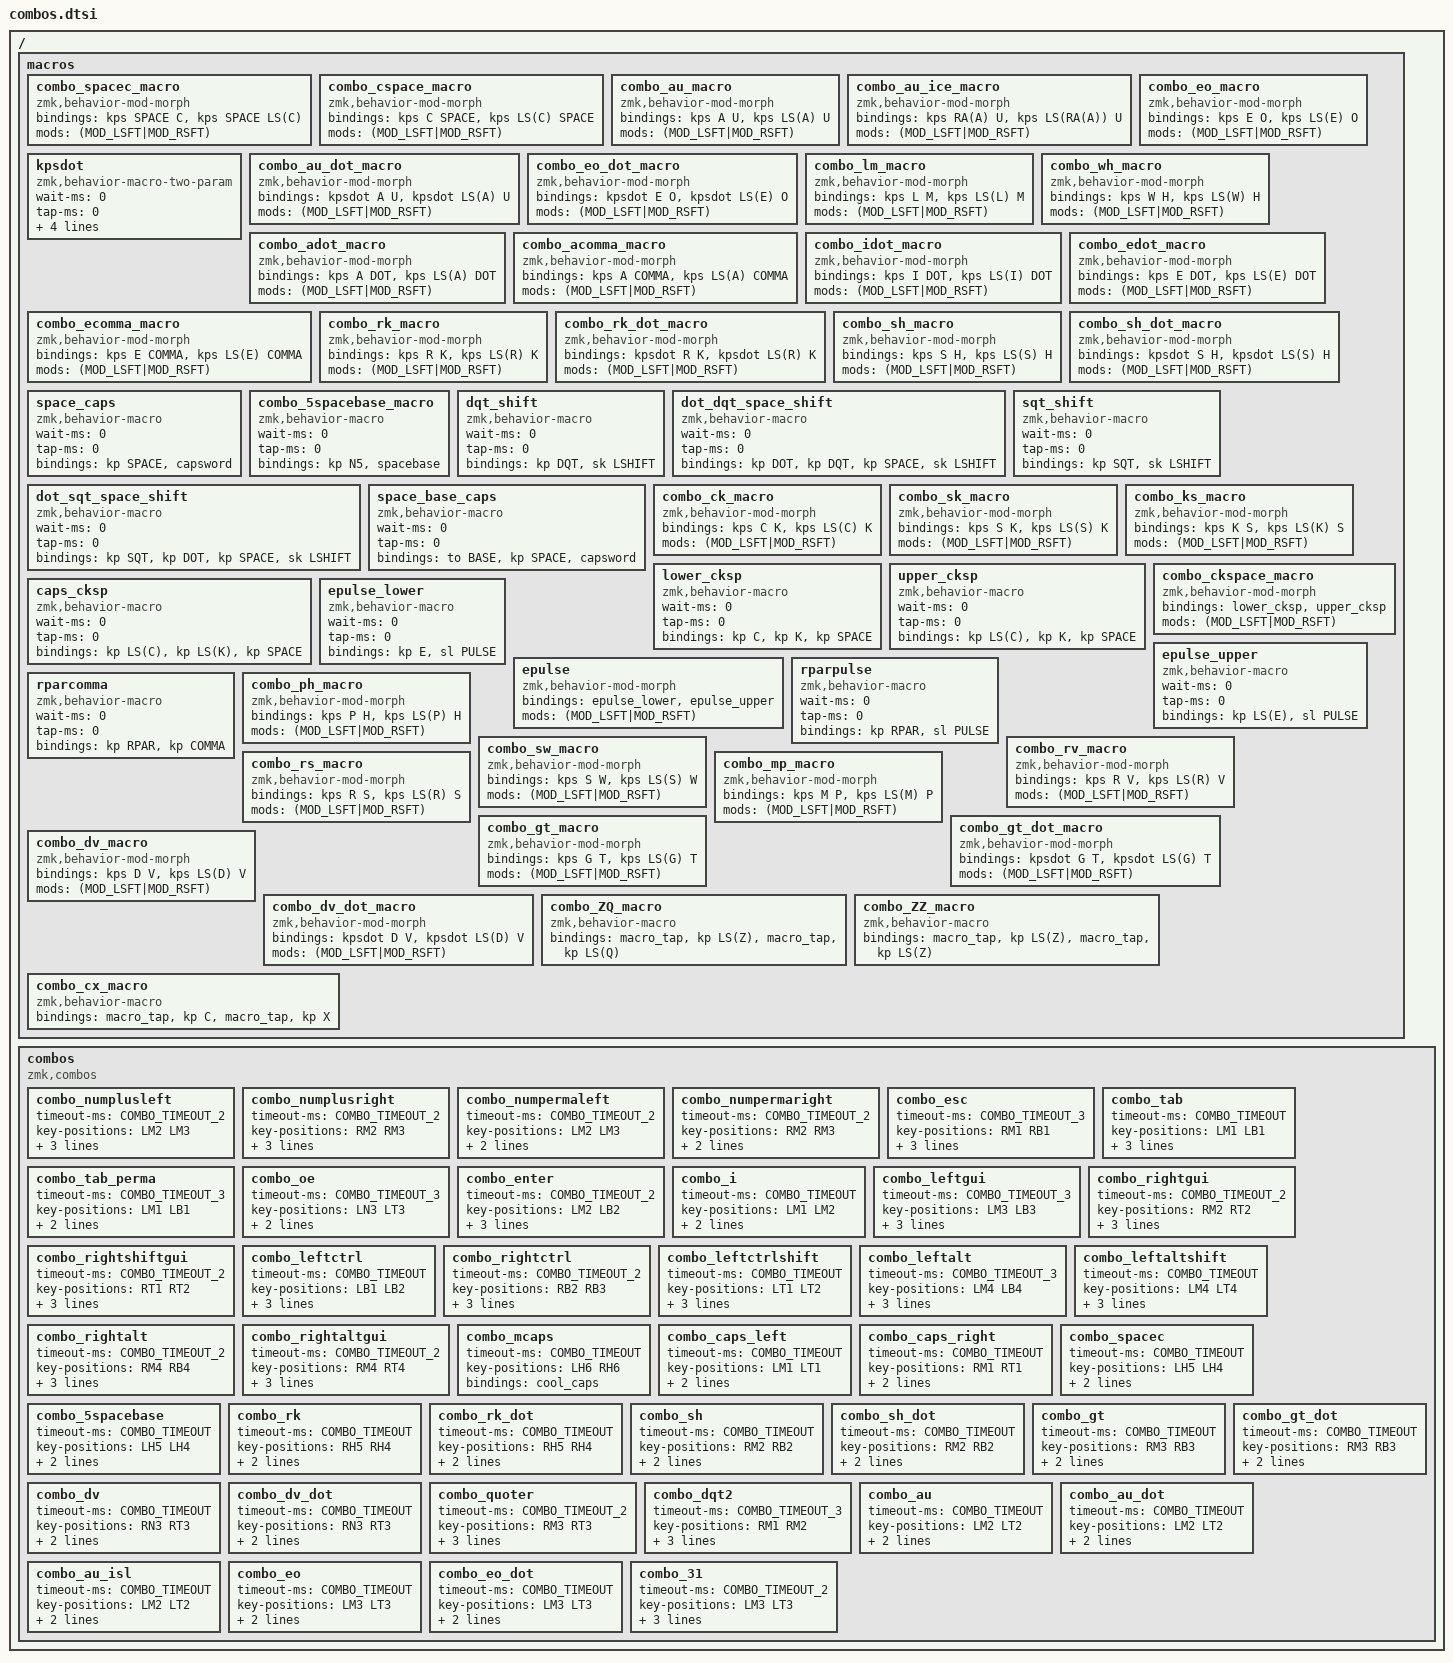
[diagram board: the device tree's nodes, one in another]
/ {
	macros {
		combo_spacec_macro: combo_spacec_macro {
			compatible = "zmk,behavior-mod-morph";
			#binding-cells = <0>;
			bindings = <&kps SPACE C>, <&kps SPACE LS(C)>;
			mods = <(MOD_LSFT|MOD_RSFT)>;
		};

		combo_cspace_macro: combo_cspace_macro {
			compatible = "zmk,behavior-mod-morph";
			#binding-cells = <0>;
			bindings = <&kps C SPACE>, <&kps LS(C) SPACE>;
			mods = <(MOD_LSFT|MOD_RSFT)>;
		};

		combo_au_macro: combo_au_macro {
			compatible = "zmk,behavior-mod-morph";
			#binding-cells = <0>;
			bindings = <&kps A U>, <&kps LS(A) U>;
			mods = <(MOD_LSFT|MOD_RSFT)>;
		};

		combo_au_ice_macro: combo_au_ice_macro {
			compatible = "zmk,behavior-mod-morph";
			#binding-cells = <0>;
			bindings = <&kps RA(A) U>, <&kps LS(RA(A)) U>;
			mods = <(MOD_LSFT|MOD_RSFT)>;
		};

		combo_eo_macro: combo_eo_macro {
			compatible = "zmk,behavior-mod-morph";
			#binding-cells = <0>;
			bindings = <&kps E O>, <&kps LS(E) O>;
			mods = <(MOD_LSFT|MOD_RSFT)>;
		};

		kpsdot: kpsdot {
			compatible = "zmk,behavior-macro-two-param";
			#binding-cells = <2>;
			wait-ms = <0>;
			tap-ms = <0>;
			bindings
				= <&macro_param_1to1>, <&kp MACRO_PLACEHOLDER>, <&kp DOT>
				, <&macro_param_2to1>, <&kp MACRO_PLACEHOLDER>, <&kp DOT>
				;
		};

		combo_au_dot_macro: combo_au_dot_macro {
			compatible = "zmk,behavior-mod-morph";
			#binding-cells = <0>;
			bindings = <&kpsdot A U>, <&kpsdot LS(A) U>;
			mods = <(MOD_LSFT|MOD_RSFT)>;
		};

		combo_eo_dot_macro: combo_eo_dot_macro {
			compatible = "zmk,behavior-mod-morph";
			#binding-cells = <0>;
			bindings = <&kpsdot E O>, <&kpsdot LS(E) O>;
			mods = <(MOD_LSFT|MOD_RSFT)>;
		};

		combo_lm_macro: combo_lm_macro {
			compatible = "zmk,behavior-mod-morph";
			#binding-cells = <0>;
			bindings = <&kps L M>, <&kps LS(L) M>;
			mods = <(MOD_LSFT|MOD_RSFT)>;
		};
		
		combo_wh_macro: combo_wh_macro {
			compatible = "zmk,behavior-mod-morph";
			#binding-cells = <0>;
			bindings = <&kps W H>, <&kps LS(W) H>;
			mods = <(MOD_LSFT|MOD_RSFT)>;
		};

		combo_adot_macro: combo_adot_macro {
			compatible = "zmk,behavior-mod-morph";
			#binding-cells = <0>;
			bindings = <&kps A DOT>, <&kps LS(A) DOT>;
			mods = <(MOD_LSFT|MOD_RSFT)>;
		};

		combo_acomma_macro: combo_acomma_macro {
			compatible = "zmk,behavior-mod-morph";
			#binding-cells = <0>;
			bindings = <&kps A COMMA>, <&kps LS(A) COMMA>;
			mods = <(MOD_LSFT|MOD_RSFT)>;
		};

		combo_idot_macro: combo_idot_macro {
			compatible = "zmk,behavior-mod-morph";
			#binding-cells = <0>;
			bindings = <&kps I DOT>, <&kps LS(I) DOT>;
			mods = <(MOD_LSFT|MOD_RSFT)>;
		};

		combo_edot_macro: combo_edot_macro {
			compatible = "zmk,behavior-mod-morph";
			#binding-cells = <0>;
			bindings = <&kps E DOT>, <&kps LS(E) DOT>;
			mods = <(MOD_LSFT|MOD_RSFT)>;
		};

		combo_ecomma_macro: combo_ecomma_macro {
			compatible = "zmk,behavior-mod-morph";
			#binding-cells = <0>;
			bindings = <&kps E COMMA>, <&kps LS(E) COMMA>;
			mods = <(MOD_LSFT|MOD_RSFT)>;
		};

		combo_rk_macro: combo_rk_macro {
			compatible = "zmk,behavior-mod-morph";
			#binding-cells = <0>;
			bindings = <&kps R K>, <&kps LS(R) K>;
			mods = <(MOD_LSFT|MOD_RSFT)>;
		};

		combo_rk_dot_macro: combo_rk_dot_macro {
			compatible = "zmk,behavior-mod-morph";
			#binding-cells = <0>;
			bindings = <&kpsdot R K>, <&kpsdot LS(R) K>;
			mods = <(MOD_LSFT|MOD_RSFT)>;
		};

		combo_sh_macro: combo_sh_macro {
			compatible = "zmk,behavior-mod-morph";
			#binding-cells = <0>;
			bindings = <&kps S H>, <&kps LS(S) H>;
			mods = <(MOD_LSFT|MOD_RSFT)>;
		};

		combo_sh_dot_macro: combo_sh_dot_macro {
			compatible = "zmk,behavior-mod-morph";
			#binding-cells = <0>;
			bindings = <&kpsdot S H>, <&kpsdot LS(S) H>;
			mods = <(MOD_LSFT|MOD_RSFT)>;
		};

		space_caps: space_caps {
			compatible = "zmk,behavior-macro";
			#binding-cells = <0>;
			wait-ms = <0>;
			tap-ms = <0>;
			bindings = <&kp SPACE &capsword>;
		};

		/* k_sqt: k_sqt { */
		/* 	compatible = "zmk,behavior-macro"; */
		/* 	#binding-cells = <0>; */
		/* 	wait-ms = <0>; */
		/* 	tap-ms = <0>; */
		/* 	bindings = <&kp K &sqt_nex>; */
		/* }; */

		combo_5spacebase_macro: combo_5spacebase_macro {
			compatible = "zmk,behavior-macro";
			#binding-cells = <0>;
			wait-ms = <0>;
			tap-ms = <0>;
			bindings = <&kp N5 &spacebase>;
		};

		dqt_shift: dqt_shift {
			compatible = "zmk,behavior-macro";
			#binding-cells = <0>;
			wait-ms = <0>;
			tap-ms = <0>;
			bindings = <&kp DQT &sk LSHIFT>;
		};

		dot_dqt_space_shift: dot_dqt_space_shift {
			compatible = "zmk,behavior-macro";
			#binding-cells = <0>;
			wait-ms = <0>;
			tap-ms = <0>;
			bindings = <&kp DOT &kp DQT &kp SPACE &sk LSHIFT>;
		};

		sqt_shift: sqt_shift {
			compatible = "zmk,behavior-macro";
			#binding-cells = <0>;
			wait-ms = <0>;
			tap-ms = <0>;
			bindings = <&kp SQT &sk LSHIFT>;
		};

		dot_sqt_space_shift: dot_sqt_space_shift {
			compatible = "zmk,behavior-macro";
			#binding-cells = <0>;
			wait-ms = <0>;
			tap-ms = <0>;
			bindings = <&kp SQT &kp DOT &kp SPACE &sk LSHIFT>;
		};

		space_base_caps: space_base_caps {
			compatible = "zmk,behavior-macro";
			#binding-cells = <0>;
			wait-ms = <0>;
			tap-ms = <0>;
			bindings = <&to BASE &kp SPACE &capsword>;
		};

		combo_ck_macro: combo_ck_macro {
			compatible = "zmk,behavior-mod-morph";
			#binding-cells = <0>;
			bindings = <&kps C K>, <&kps LS(C) K>;
			mods = <(MOD_LSFT|MOD_RSFT)>;
		};

		combo_sk_macro: combo_sk_macro {
			compatible = "zmk,behavior-mod-morph";
			#binding-cells = <0>;
			bindings = <&kps S K>, <&kps LS(S) K>;
			mods = <(MOD_LSFT|MOD_RSFT)>;
		};

		combo_ks_macro: combo_ks_macro {
			compatible = "zmk,behavior-mod-morph";
			#binding-cells = <0>;
			bindings = <&kps K S>, <&kps LS(K) S>;
			mods = <(MOD_LSFT|MOD_RSFT)>;
		};
    
		lower_cksp: lower_cksp {
			compatible = "zmk,behavior-macro";
			#binding-cells = <0>;
			wait-ms = <0>;
			tap-ms = <0>;
			bindings = <&kp C &kp K &kp SPACE>;
		};

		upper_cksp: upper_cksp {
			compatible = "zmk,behavior-macro";
			#binding-cells = <0>;
			wait-ms = <0>;
			tap-ms = <0>;
			bindings = <&kp LS(C) &kp K &kp SPACE>;
		};

		combo_ckspace_macro: combo_ckspace_macro {
			compatible = "zmk,behavior-mod-morph";
			#binding-cells = <0>;
			bindings = <&lower_cksp>, <&upper_cksp>;
			mods = <(MOD_LSFT|MOD_RSFT)>;
		};

		caps_cksp: caps_cksp {
			compatible = "zmk,behavior-macro";
			#binding-cells = <0>;
			wait-ms = <0>;
			tap-ms = <0>;
			bindings = <&kp LS(C) &kp LS(K) &kp SPACE>;
		};

		epulse_lower: epulse_lower {
			compatible = "zmk,behavior-macro";
			#binding-cells = <0>;
			wait-ms = <0>;
			tap-ms = <0>;
			bindings = <&kp E &sl PULSE>;
		};

		epulse_upper: epulse_upper {
			compatible = "zmk,behavior-macro";
			#binding-cells = <0>;
			wait-ms = <0>;
			tap-ms = <0>;
			bindings = <&kp LS(E) &sl PULSE>;
		};

		epulse: epulse {
			compatible = "zmk,behavior-mod-morph";
			#binding-cells = <0>;
			bindings = <&epulse_lower>, <&epulse_upper>;
			mods = <(MOD_LSFT|MOD_RSFT)>;
		};

		rparpulse: rparpulse {
			compatible = "zmk,behavior-macro";
			#binding-cells = <0>;
			wait-ms = <0>;
			tap-ms = <0>;
			bindings = <&kp RPAR &sl PULSE>;
		};
    
		rparcomma: rparcomma {
			compatible = "zmk,behavior-macro";
			#binding-cells = <0>;
			wait-ms = <0>;
			tap-ms = <0>;
			bindings = <&kp RPAR &kp COMMA>;
		};

		/* wh_and_kp: wh_and_kp { */
		/* 	compatible = "zmk,behavior-macro-one-param"; */
		/* 	#binding-cells = <1>; */
		/* 	bindings =  <&kp W>, */
		/* 	<&macro_param_1to2>, <&kps H MACRO_PLACEHOLDER>; */
		/* }; */
		/**/
		/* cwh_and_kp: cwh_and_kp { */
		/* 	compatible = "zmk,behavior-macro-one-param"; */
		/* 	#binding-cells = <1>; */
		/* 	bindings =  <&kp LS(W)>, */
		/* 	<&macro_param_1to2>, <&kps H MACRO_PLACEHOLDER>; */
		/* }; */
		/**/
		/* combo_wha_macro: combo_wha_macro { */
		/* 	compatible = "zmk,behavior-mod-morph"; */
		/* 	#binding-cells = <0>; */
		/* 	bindings = <&wh_and_kp A>, <&cwh_and_kp A>; */
		/* 	mods = <(MOD_LSFT|MOD_RSFT)>; */
		/* }; */
		
		combo_ph_macro: combo_ph_macro {
			compatible = "zmk,behavior-mod-morph";
			#binding-cells = <0>;
			bindings = <&kps P H>, <&kps LS(P) H>;
			mods = <(MOD_LSFT|MOD_RSFT)>;
		};
		
		combo_sw_macro: combo_sw_macro {
			compatible = "zmk,behavior-mod-morph";
			#binding-cells = <0>;
			bindings = <&kps S W>, <&kps LS(S) W>;
			mods = <(MOD_LSFT|MOD_RSFT)>;
		};
		
		combo_rv_macro: combo_rv_macro {
			compatible = "zmk,behavior-mod-morph";
			#binding-cells = <0>;
			bindings = <&kps R V>, <&kps LS(R) V>;
			mods = <(MOD_LSFT|MOD_RSFT)>;
		};
		
		combo_rs_macro: combo_rs_macro {
			compatible = "zmk,behavior-mod-morph";
			#binding-cells = <0>;
			bindings = <&kps R S>, <&kps LS(R) S>;
			mods = <(MOD_LSFT|MOD_RSFT)>;
		};
		
		combo_mp_macro: combo_mp_macro {
			compatible = "zmk,behavior-mod-morph";
			#binding-cells = <0>;
			bindings = <&kps M P>, <&kps LS(M) P>;
			mods = <(MOD_LSFT|MOD_RSFT)>;
		};
		
		combo_gt_macro: combo_gt_macro {
			compatible = "zmk,behavior-mod-morph";
			#binding-cells = <0>;
			bindings = <&kps G T>, <&kps LS(G) T>;
			mods = <(MOD_LSFT|MOD_RSFT)>;
		};

		combo_gt_dot_macro: combo_gt_dot_macro {
			compatible = "zmk,behavior-mod-morph";
			#binding-cells = <0>;
			bindings = <&kpsdot G T>, <&kpsdot LS(G) T>;
			mods = <(MOD_LSFT|MOD_RSFT)>;
		};

		combo_dv_macro: combo_dv_macro {
			compatible = "zmk,behavior-mod-morph";
			#binding-cells = <0>;
			bindings = <&kps D V>, <&kps LS(D) V>;
			mods = <(MOD_LSFT|MOD_RSFT)>;
		};

		combo_dv_dot_macro: combo_dv_dot_macro {
			compatible = "zmk,behavior-mod-morph";
			#binding-cells = <0>;
			bindings = <&kpsdot D V>, <&kpsdot LS(D) V>;
			mods = <(MOD_LSFT|MOD_RSFT)>;
		};
		
		combo_ZQ_macro: combo_ZQ_macro {
			compatible = "zmk,behavior-macro";
			#binding-cells = <0>;
      bindings = <&macro_tap &kp LS(Z)>, <&macro_tap &kp LS(Q)>;
		};

		combo_ZZ_macro: combo_ZZ_macro {
			compatible = "zmk,behavior-macro";
			#binding-cells = <0>;
			bindings = <&macro_tap &kp LS(Z)>, <&macro_tap &kp LS(Z)>;
		};
		
		combo_cx_macro: combo_cx_macro {
			compatible = "zmk,behavior-macro";
			#binding-cells = <0>;
			bindings = <&macro_tap &kp C>, <&macro_tap &kp X>;
		};
	};
};

/ {
	
	combos {
		compatible = "zmk,combos";
		
		#define COMBO_TIMEOUT_1 10
		#define COMBO_TIMEOUT_2 20
		#define COMBO_TIMEOUT_3 35
		#define COMBO_TIMEOUT 50
    
		combo_numplusleft {
			timeout-ms = <COMBO_TIMEOUT_2>;
			key-positions = <LM2 LM3>;
			bindings = <&num_plus_or_perma>;
			layers = <BASE BASE_DOT NAV_WORD NAV_WORD_GUI NAV_WORD_ALT NAV_WORD_SHIFT NAV_WORD_CTRL NAV_WORD_SHIFT_CTRL NAV_WORD_SHIFT_GUI NAV_WORD_CTRL_GUI VIM_WORD PAGE_WORD NUM_WORD NUM_WORD_MODDED NEXUS NEXUS_LOCK PULSE PULSE_LOCK TRICODER TAB_OVERLAY BACKSPACER ICE>; 
		};

		combo_numplusright {
			timeout-ms = <COMBO_TIMEOUT_2>;
			key-positions = <RM2 RM3>;
			bindings = <&num_plus_or_perma>;
			layers = <BASE BASE_DOT NAV_WORD NAV_WORD_GUI NAV_WORD_ALT NAV_WORD_SHIFT NAV_WORD_CTRL NAV_WORD_SHIFT_CTRL NAV_WORD_SHIFT_GUI NAV_WORD_CTRL_GUI VIM_WORD PAGE_WORD NUM_WORD NUM_WORD_MODDED NEXUS NEXUS_LOCK PULSE PULSE_LOCK TRICODER TAB_OVERLAY BACKSPACER ICE>; 
		};

		combo_numpermaleft {
			timeout-ms = <COMBO_TIMEOUT_2>;
			key-positions = <LM2 LM3>;
			bindings = <&nums_perma>;
			layers = <NUM_WORD_PLUS>; 
		};

		combo_numpermaright {
			timeout-ms = <COMBO_TIMEOUT_2>;
			key-positions = <RM2 RM3>;
			bindings = <&nums_perma>;
			layers = <NUM_WORD_PLUS>; 
		};

		combo_esc {
			timeout-ms = <COMBO_TIMEOUT_3>;
			key-positions = <RM1 RB1>;
			bindings = <&escaper>;
			layers = <BASE BASE_DOT NAV_WORD NAV_WORD_GUI NAV_WORD_ALT NAV_WORD_SHIFT NAV_WORD_CTRL NAV_WORD_SHIFT_CTRL NAV_WORD_SHIFT_GUI NAV_WORD_CTRL_GUI VIM_WORD PAGE_WORD NUM_WORD NUM_WORD_PLUS NUM_WORD_PERMA NUM_WORD_MODDED NEXUS NEXUS_LOCK PULSE PULSE_LOCK TRICODER TAB_OVERLAY BACKSPACER ICE ICE_HOLD MOUSE_SLOW MOUSE_WARP>; 
		};

		
		combo_tab {
			timeout-ms = <COMBO_TIMEOUT>;
			/* key-positions = <RT2 RT3>; */
			key-positions = <LM1 LB1>;
			bindings = <&tabber>;
			layers = <BASE BASE_DOT NAV_WORD NAV_WORD_GUI NAV_WORD_ALT NAV_WORD_SHIFT NAV_WORD_CTRL NAV_WORD_SHIFT_CTRL NAV_WORD_SHIFT_GUI NAV_WORD_CTRL_GUI VIM_WORD PAGE_WORD NUM_WORD NUM_WORD_PLUS NUM_WORD_PERMA NUM_WORD_MODDED NEXUS NEXUS_LOCK PULSE PULSE_LOCK TRICODER TAB_OVERLAY BACKSPACER ICE>; 
		};
		
		combo_tab_perma {
			timeout-ms = <COMBO_TIMEOUT_3>;
			/* key-positions = <RT2 RT3>; */
			key-positions = <LM1 LB1>;
			bindings = <&kp TAB>;
			layers = <NUM_WORD_PERMA>; 
		};
		
		combo_oe {
			timeout-ms = <COMBO_TIMEOUT_3>;
			key-positions = <LN3 LT3>;
			bindings = <&kp RA(P)>;
			layers = <BASE>;
		};
		
		/* combo_dotonnum { */
		/* 	timeout-ms = <COMBO_TIMEOUT_2>; */
		/* 	key-positions = <LT2 LT3>; */
		/* 	bindings = <&num_adapt>; */
		/* 	layers = <NUM_WORD NUM_WORD_PLUS NUM_WORD_PERMA NUM_WORD_MODDED>; */
		/* }; */
		
		combo_enter {
			timeout-ms = <COMBO_TIMEOUT_2>;
			key-positions = <LM2 LB2>;
			bindings = <&enterer>;
			layers = <BASE BASE_DOT NAV_WORD NAV_WORD_GUI NAV_WORD_ALT NAV_WORD_SHIFT NAV_WORD_CTRL NAV_WORD_SHIFT_CTRL NAV_WORD_SHIFT_GUI NAV_WORD_CTRL_GUI VIM_WORD PAGE_WORD NUM_WORD NUM_WORD_PLUS NUM_WORD_PERMA NUM_WORD_MODDED NEXUS NEXUS_LOCK PULSE PULSE_LOCK TRICODER TAB_OVERLAY BACKSPACER ICE>; 
		};
		
		combo_i {
			timeout-ms = <COMBO_TIMEOUT>;
			key-positions = <LM1 LM2>;
			bindings = <&kp I>;
			layers = <BASE>; 
		};
		
		combo_leftgui {
			timeout-ms = <COMBO_TIMEOUT_3>;
			key-positions = <LM3 LB3>;
			bindings = <&sk LGUI>;
			layers = <BASE BASE_DOT NAV_WORD NAV_WORD_GUI NAV_WORD_ALT NAV_WORD_SHIFT NAV_WORD_CTRL NAV_WORD_SHIFT_CTRL NAV_WORD_SHIFT_GUI NAV_WORD_CTRL_GUI VIM_WORD PAGE_WORD NUM_WORD NUM_WORD_PLUS NUM_WORD_PERMA NUM_WORD_MODDED NEXUS NEXUS_LOCK PULSE PULSE_LOCK TRICODER TAB_OVERLAY BACKSPACER ICE>; 
		};
		
		combo_rightgui {
			timeout-ms = <COMBO_TIMEOUT_2>;
			key-positions = <RM2 RT2>;
			bindings = <&sk RGUI>;
			layers = <BASE BASE_DOT NAV_WORD NAV_WORD_GUI NAV_WORD_ALT NAV_WORD_SHIFT NAV_WORD_CTRL NAV_WORD_SHIFT_CTRL NAV_WORD_SHIFT_GUI NAV_WORD_CTRL_GUI VIM_WORD PAGE_WORD NUM_WORD NUM_WORD_PLUS NUM_WORD_PERMA NUM_WORD_MODDED NEXUS NEXUS_LOCK PULSE PULSE_LOCK TRICODER TAB_OVERLAY BACKSPACER ICE>; 
		};
		
		combo_rightshiftgui {
			timeout-ms = <COMBO_TIMEOUT_2>;
			key-positions = <RT1 RT2>;
			bindings = <&sk LS(RGUI)>;
			layers = <BASE BASE_DOT NAV_WORD NAV_WORD_GUI NAV_WORD_ALT NAV_WORD_SHIFT NAV_WORD_CTRL NAV_WORD_SHIFT_CTRL NAV_WORD_SHIFT_GUI NAV_WORD_CTRL_GUI VIM_WORD PAGE_WORD NUM_WORD NUM_WORD_PLUS NUM_WORD_PERMA NUM_WORD_MODDED NEXUS NEXUS_LOCK PULSE PULSE_LOCK TRICODER TAB_OVERLAY BACKSPACER ICE>; 
		};
		
		combo_leftctrl {
			timeout-ms = <COMBO_TIMEOUT>;
			key-positions = <LB1 LB2>;
			bindings = <&sk LCTRL>;
			layers = <BASE BASE_DOT NAV_WORD NAV_WORD_GUI NAV_WORD_ALT NAV_WORD_SHIFT NAV_WORD_CTRL NAV_WORD_SHIFT_CTRL NAV_WORD_SHIFT_GUI NAV_WORD_CTRL_GUI VIM_WORD PAGE_WORD NUM_WORD NUM_WORD_PLUS NUM_WORD_PERMA NUM_WORD_MODDED NEXUS NEXUS_LOCK PULSE PULSE_LOCK TRICODER TAB_OVERLAY BACKSPACER ICE>; 
		};
		
		/* combo_leftctrl2 { */
		/* 	timeout-ms = <COMBO_TIMEOUT_3>; */
		/* 	key-positions = <LT3 LN3>; */
		/* 	bindings = <&sk LCTRL>; */
		/* 	layers = <BASE NAV_WORD NUM_WORD NUM_WORD_PLUS NUM_WORD_PERMA NUM_WORD_MODDED NEXUS NEXUS_LOCK PULSE PULSE_LOCK TRICODER TAB_OVERLAY>;  */
		/* }; */
		
		combo_rightctrl {
			timeout-ms = <COMBO_TIMEOUT_2>;
			key-positions = <RB2 RB3>;
			bindings = <&sk RCTRL>;
			layers = <BASE BASE_DOT NAV_WORD NAV_WORD_GUI NAV_WORD_ALT NAV_WORD_SHIFT NAV_WORD_CTRL NAV_WORD_SHIFT_CTRL NAV_WORD_SHIFT_GUI NAV_WORD_CTRL_GUI VIM_WORD PAGE_WORD NUM_WORD NUM_WORD_PLUS NUM_WORD_PERMA NUM_WORD_MODDED NEXUS NEXUS_LOCK PULSE PULSE_LOCK TRICODER TAB_OVERLAY BACKSPACER ICE>; 
		};

		combo_leftctrlshift {
			timeout-ms = <COMBO_TIMEOUT>;
			key-positions = <LT1 LT2>;
			bindings = <&sk LC(LSHIFT)>;
			layers = <BASE BASE_DOT NAV_WORD NAV_WORD_GUI NAV_WORD_ALT NAV_WORD_SHIFT NAV_WORD_CTRL NAV_WORD_SHIFT_CTRL NAV_WORD_SHIFT_GUI NAV_WORD_CTRL_GUI VIM_WORD PAGE_WORD NUM_WORD NUM_WORD_PLUS NUM_WORD_PERMA NUM_WORD_MODDED NEXUS NEXUS_LOCK PULSE PULSE_LOCK TRICODER TAB_OVERLAY BACKSPACER ICE>; 
		};
		
		combo_leftalt {
			timeout-ms = <COMBO_TIMEOUT_3>;
			key-positions = <LM4 LB4>;
			bindings = <&sk LALT>;
			layers = <BASE BASE_DOT NAV_WORD NAV_WORD_GUI NAV_WORD_ALT NAV_WORD_SHIFT NAV_WORD_CTRL NAV_WORD_SHIFT_CTRL NAV_WORD_SHIFT_GUI NAV_WORD_CTRL_GUI VIM_WORD PAGE_WORD NUM_WORD NUM_WORD_PLUS NUM_WORD_PERMA NUM_WORD_MODDED NEXUS NEXUS_LOCK PULSE PULSE_LOCK TRICODER TAB_OVERLAY BACKSPACER ICE>; 
		};
		
		combo_leftaltshift {
			timeout-ms = <COMBO_TIMEOUT>;
			key-positions = <LM4 LT4>;
			bindings = <&sk LS(LALT)>;
			layers = <BASE BASE_DOT NAV_WORD NAV_WORD_GUI NAV_WORD_ALT NAV_WORD_SHIFT NAV_WORD_CTRL NAV_WORD_SHIFT_CTRL NAV_WORD_SHIFT_GUI NAV_WORD_CTRL_GUI VIM_WORD PAGE_WORD NUM_WORD NUM_WORD_PLUS NUM_WORD_PERMA NUM_WORD_MODDED NEXUS NEXUS_LOCK PULSE PULSE_LOCK TRICODER TAB_OVERLAY BACKSPACER ICE>; 
		};
		
		combo_rightalt {
			timeout-ms = <COMBO_TIMEOUT_2>;
			key-positions = <RM4 RB4>;
			bindings = <&sk LALT>;
			layers = <BASE BASE_DOT NAV_WORD NAV_WORD_GUI NAV_WORD_ALT NAV_WORD_SHIFT NAV_WORD_CTRL NAV_WORD_SHIFT_CTRL NAV_WORD_SHIFT_GUI NAV_WORD_CTRL_GUI VIM_WORD PAGE_WORD NUM_WORD NUM_WORD_PLUS NUM_WORD_PERMA NUM_WORD_MODDED NEXUS NEXUS_LOCK PULSE PULSE_LOCK TRICODER TAB_OVERLAY BACKSPACER ICE>; 
		};

		combo_rightaltgui {
			timeout-ms = <COMBO_TIMEOUT_2>;
			key-positions = <RM4 RT4>;
			bindings = <&sk LG(LALT)>;
			layers = <BASE BASE_DOT NAV_WORD NAV_WORD_GUI NAV_WORD_ALT NAV_WORD_SHIFT NAV_WORD_CTRL NAV_WORD_SHIFT_CTRL NAV_WORD_SHIFT_GUI NAV_WORD_CTRL_GUI VIM_WORD PAGE_WORD NUM_WORD NUM_WORD_PLUS NUM_WORD_PERMA NUM_WORD_MODDED NEXUS NEXUS_LOCK PULSE PULSE_LOCK TRICODER TAB_OVERLAY BACKSPACER ICE>;
		};
		
		combo_mcaps {
			timeout-ms = <COMBO_TIMEOUT>;
			key-positions = <LH6 RH6>;
			/* bindings = <&mpcaps>; */
			bindings = <&cool_caps>;
		};
		
		combo_caps_left {
			timeout-ms = <COMBO_TIMEOUT>;
			key-positions = <LM1 LT1>;
			bindings = <&capsword>;
			layers = <BASE>;
		};
		
		combo_caps_right {
			timeout-ms = <COMBO_TIMEOUT>;
			key-positions = <RM1 RT1>;
			bindings = <&capsword>;
			layers = <BASE>;
		};

		combo_spacec {
			timeout-ms = <COMBO_TIMEOUT>;
			key-positions = <LH5 LH4>;
			bindings = <&combo_spacec_macro>;
			layers = <BASE>;
		};

		combo_5spacebase {
			timeout-ms = <COMBO_TIMEOUT>;
			key-positions = <LH5 LH4>;
			bindings = <&combo_5spacebase_macro>;
			layers = <NUM_WORD_PLUS NUM_WORD_MODDED>;
		};

		combo_rk {
			timeout-ms = <COMBO_TIMEOUT>;
			key-positions = <RH5 RH4>;
			bindings = <&combo_rk_macro>;
			layers = <BASE>;
		};

		combo_rk_dot {
			timeout-ms = <COMBO_TIMEOUT>;
			key-positions = <RH5 RH4>;
			bindings = <&combo_rk_dot_macro>;
			layers = <BASE_DOT>;
		};

		combo_sh {
			timeout-ms = <COMBO_TIMEOUT>;
			key-positions = <RM2 RB2>;
			bindings = <&combo_sh_macro>;
			layers = <BASE>;
		};

		combo_sh_dot {
			timeout-ms = <COMBO_TIMEOUT>;
			key-positions = <RM2 RB2>;
			bindings = <&combo_sh_dot_macro>;
			layers = <BASE_DOT>;
		};

		combo_gt {
			timeout-ms = <COMBO_TIMEOUT>;
			key-positions = <RM3 RB3>;
			bindings = <&combo_gt_macro>;
			layers = <BASE>;
		};

		combo_gt_dot {
			timeout-ms = <COMBO_TIMEOUT>;
			key-positions = <RM3 RB3>;
			bindings = <&combo_gt_dot_macro>;
			layers = <BASE_DOT>;
		};

		combo_dv {
			timeout-ms = <COMBO_TIMEOUT>;
			key-positions = <RN3 RT3>;
			bindings = <&combo_dv_macro>;
			layers = <BASE>;
		};

		combo_dv_dot {
			timeout-ms = <COMBO_TIMEOUT>;
			key-positions = <RN3 RT3>;
			bindings = <&combo_dv_dot_macro>;
			layers = <BASE_DOT>;
		};

		combo_quoter {
			timeout-ms = <COMBO_TIMEOUT_2>;
			key-positions = <RM3 RT3>;
      /* tristateið brotnar strax sem er bara gott, til að nota ýtiru á þorn takkann áður en ert búinn að sleppa comboinu */
			/* bindings = <&quoter>;  */
      /* eeeeh actually ef ég held dqt og dqt2 er quoter hér óþarft */
			bindings = <&kp DQT>;
			layers = <BASE BASE_DOT NAV_WORD NAV_WORD_GUI NAV_WORD_ALT NAV_WORD_SHIFT NAV_WORD_CTRL NAV_WORD_SHIFT_CTRL NAV_WORD_SHIFT_GUI NAV_WORD_CTRL_GUI VIM_WORD PAGE_WORD NUM_WORD NUM_WORD_PLUS NUM_WORD_PERMA NUM_WORD_MODDED NEXUS NEXUS_LOCK PULSE PULSE_LOCK TRICODER TAB_OVERLAY BACKSPACER ICE>; 
		};

		/* Merged into combo_quoter so RM3+RT3 quote behavior stays consistent across layers. */
		/* combo_dqt { */
		/* 	timeout-ms = <COMBO_TIMEOUT_2>; */
		/* 	key-positions = <RM3 RT3>; */
		/* 	bindings = <&kp DQT>; */
		/* 	layers = <NEXUS NEXUS_LOCK PULSE_LOCK TRICODER>; */
		/* }; */

		combo_dqt2 {
			timeout-ms = <COMBO_TIMEOUT_3>;
			key-positions = <RM1 RM2>;
			bindings = <&kp DQT>;
			layers = <BASE BASE_DOT NAV_WORD NAV_WORD_GUI NAV_WORD_ALT NAV_WORD_SHIFT NAV_WORD_CTRL NAV_WORD_SHIFT_CTRL NAV_WORD_SHIFT_GUI NAV_WORD_CTRL_GUI VIM_WORD PAGE_WORD NUM_WORD NUM_WORD_PLUS NUM_WORD_PERMA NUM_WORD_MODDED NEXUS NEXUS_LOCK PULSE PULSE_LOCK TRICODER TAB_OVERLAY BACKSPACER ICE>;
		};

		combo_au {
			timeout-ms = <COMBO_TIMEOUT>;
			key-positions = <LM2 LT2>;
			bindings = <&combo_au_macro>;
			layers = <BASE>;
		};

		combo_au_dot {
			timeout-ms = <COMBO_TIMEOUT>;
			key-positions = <LM2 LT2>;
			bindings = <&combo_au_dot_macro>;
			layers = <BASE_DOT>;
		};
		
		combo_au_isl {
			timeout-ms = <COMBO_TIMEOUT>;
			key-positions = <LM2 LT2>;
			bindings = <&combo_au_ice_macro>;
			layers = <ICE>;
		};
		
		combo_eo {
			timeout-ms = <COMBO_TIMEOUT>;
			key-positions = <LM3 LT3>;
			bindings = <&combo_eo_macro>;
			layers = <BASE>;
		};

		combo_eo_dot {
			timeout-ms = <COMBO_TIMEOUT>;
			key-positions = <LM3 LT3>;
			bindings = <&combo_eo_dot_macro>;
			layers = <BASE_DOT>;
		};

		/* combo_80 {
			timeout-ms = <COMBO_TIMEOUT_2>;
			key-positions = <RM3 RT3>;
			bindings = <&kps N8 N0>;
			layers = <NUM_WORD NUM_WORD_PLUS NUM_WORD_PERMA NUM_WORD_MODDED>;
		}; */
		
		combo_31 {
			timeout-ms = <COMBO_TIMEOUT_2>;
			key-positions = <LM3 LT3>;
			bindings = <&kps N3 N1>;
			layers = <NUM_WORD NUM_WORD_PLUS NUM_WORD_PERMA NUM_WORD_MODDED>;
		};
		
	};
};
